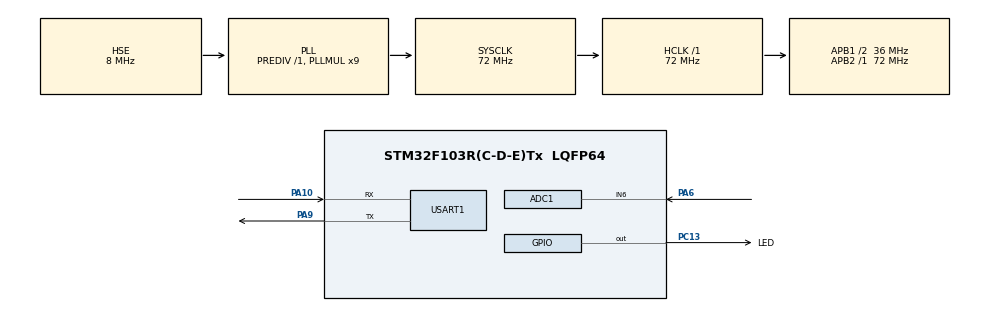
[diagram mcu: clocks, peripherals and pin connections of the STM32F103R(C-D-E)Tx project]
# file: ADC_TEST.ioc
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ADC1.Channel-0\#ChannelRegularConversion=ADC_CHANNEL_6
ADC1.ContinuousConvMode=ENABLE
ADC1.NbrOfConversionFlag=1
ADC1.Rank-0\#ChannelRegularConversion=1
ADC1.SamplingTime-0\#ChannelRegularConversion=ADC_SAMPLETIME_1CYCLE_5
ADC1.master=1
Mcu.Family=STM32F1
Mcu.Name=STM32F103R(C-D-E)Tx
Mcu.Package=LQFP64
NVIC.ADC1_2_IRQn=true\:0\:0\:false\:false\:true\:true\:true\:true
NVIC.PriorityGroup=NVIC_PRIORITYGROUP_4
PA10.Mode=Asynchronous
PA10.Signal=USART1_RX
PA13.Mode=Serial_Wire
PA13.Signal=SYS_JTMS-SWDIO
PA14.Mode=Serial_Wire
PA14.Signal=SYS_JTCK-SWCLK
PA6.Signal=ADCx_IN6
PA9.Mode=Asynchronous
PA9.Signal=USART1_TX
PC13-TAMPER-RTC.GPIO_Label=LED
PC13-TAMPER-RTC.PinState=GPIO_PIN_SET
PC13-TAMPER-RTC.Signal=GPIO_Output
PD0-OSC_IN.Mode=HSE-External-Oscillator
PD0-OSC_IN.Signal=RCC_OSC_IN
PD1-OSC_OUT.Mode=HSE-External-Oscillator
PD1-OSC_OUT.Signal=RCC_OSC_OUT
ProjectManager.HeapSize=0x200
ProjectManager.StackSize=0x400
ProjectManager.TargetToolchain=MDK-ARM V5.32
RCC.AHBFreq_Value=72000000
RCC.APB1CLKDivider=RCC_HCLK_DIV2
RCC.APB1Freq_Value=36000000
RCC.APB1TimFreq_Value=72000000
RCC.APB2Freq_Value=72000000
RCC.APB2TimFreq_Value=72000000
RCC.HCLKFreq_Value=72000000
RCC.PLLMUL=RCC_PLL_MUL9
RCC.PLLSourceVirtual=RCC_PLLSOURCE_HSE
RCC.SYSCLKFreq_VALUE=72000000
RCC.SYSCLKSource=RCC_SYSCLKSOURCE_PLLCLK
RCC.USBFreq_Value=72000000
SH.ADCx_IN6.0=ADC1_IN6,IN6
USART1.VirtualMode=VM_ASYNC
board=custom

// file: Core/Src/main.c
/* USER CODE BEGIN Header */
/**
  ******************************************************************************
  * @file           : main.c
  * @brief          : Main program body
  ******************************************************************************
  * @attention
  *
  * Copyright (c) 2023 STMicroelectronics.
  * All rights reserved.
  *
  * This software is licensed under terms that can be found in the LICENSE file
  * in the root directory of this software component.
  * If no LICENSE file comes with this software, it is provided AS-IS.
  *
  ******************************************************************************
  */
/* USER CODE END Header */
#include "main.h"
#include "adc.h"
#include "usart.h"
#include "gpio.h"
#include <stdio.h>
int fputc(int ch, FILE *f){
  HAL_UART_Transmit(&huart1, (uint8_t *)&ch, 1, 0xffff);
  return ch;
}
int fgetc(FILE *f){
  uint8_t ch = 0;
  HAL_UART_Receive(&huart1, &ch, 1, 0xffff);
  return ch;
}

void SystemClock_Config(void);

int main(void)
{
  /* USER CODE BEGIN 1 */
    uint16_t value;
  /* USER CODE END 1 */

  /* MCU Configuration--------------------------------------------------------*/

  /* Reset of all peripherals, Initializes the Flash interface and the Systick. */
  HAL_Init();

  /* Configure the system clock */
  SystemClock_Config();

  /* Initialize all configured peripherals */
  MX_GPIO_Init();
  MX_ADC1_Init();
  MX_USART1_UART_Init();

  HAL_ADC_Start(&hadc1);

  /* Infinite loop */
  while (1)
  {
    value = HAL_ADC_GetValue(&hadc1);
//    /* USER CODE BEGIN 3 */
//      printf("%d \r\n", value);
      HAL_UART_Transmit(&huart1, (uint8_t *)&value, 1, 0xFFFF);
      HAL_GPIO_TogglePin(LED_GPIO_Port, LED_Pin);
      HAL_Delay(500);
  }
  /* USER CODE END 3 */
}

void SystemClock_Config(void)
{
  RCC_OscInitTypeDef RCC_OscInitStruct = {0};
  RCC_ClkInitTypeDef RCC_ClkInitStruct = {0};
  RCC_PeriphCLKInitTypeDef PeriphClkInit = {0};

  /** Initializes the RCC Oscillators according to the specified parameters
  * in the RCC_OscInitTypeDef structure.
  */
  RCC_OscInitStruct.OscillatorType = RCC_OSCILLATORTYPE_HSE;
  RCC_OscInitStruct.HSEState = RCC_HSE_ON;
  RCC_OscInitStruct.HSEPredivValue = RCC_HSE_PREDIV_DIV1;
  RCC_OscInitStruct.HSIState = RCC_HSI_ON;
  RCC_OscInitStruct.PLL.PLLState = RCC_PLL_ON;
  RCC_OscInitStruct.PLL.PLLSource = RCC_PLLSOURCE_HSE;
  RCC_OscInitStruct.PLL.PLLMUL = RCC_PLL_MUL9;
  if (HAL_RCC_OscConfig(&RCC_OscInitStruct) != HAL_OK)
  {
    Error_Handler();
  }

  /** Initializes the CPU, AHB and APB buses clocks
  */
  RCC_ClkInitStruct.ClockType = RCC_CLOCKTYPE_HCLK|RCC_CLOCKTYPE_SYSCLK
                              |RCC_CLOCKTYPE_PCLK1|RCC_CLOCKTYPE_PCLK2;
  RCC_ClkInitStruct.SYSCLKSource = RCC_SYSCLKSOURCE_PLLCLK;
  RCC_ClkInitStruct.AHBCLKDivider = RCC_SYSCLK_DIV1;
  RCC_ClkInitStruct.APB1CLKDivider = RCC_HCLK_DIV2;
  RCC_ClkInitStruct.APB2CLKDivider = RCC_HCLK_DIV1;

  if (HAL_RCC_ClockConfig(&RCC_ClkInitStruct, FLASH_LATENCY_2) != HAL_OK)
  {
    Error_Handler();
  }
  PeriphClkInit.PeriphClockSelection = RCC_PERIPHCLK_ADC;
  PeriphClkInit.AdcClockSelection = RCC_ADCPCLK2_DIV2;
  if (HAL_RCCEx_PeriphCLKConfig(&PeriphClkInit) != HAL_OK)
  {
    Error_Handler();
  }
}

void Error_Handler(void)
{
  __disable_irq();
  while (1)
  {
  }
}
